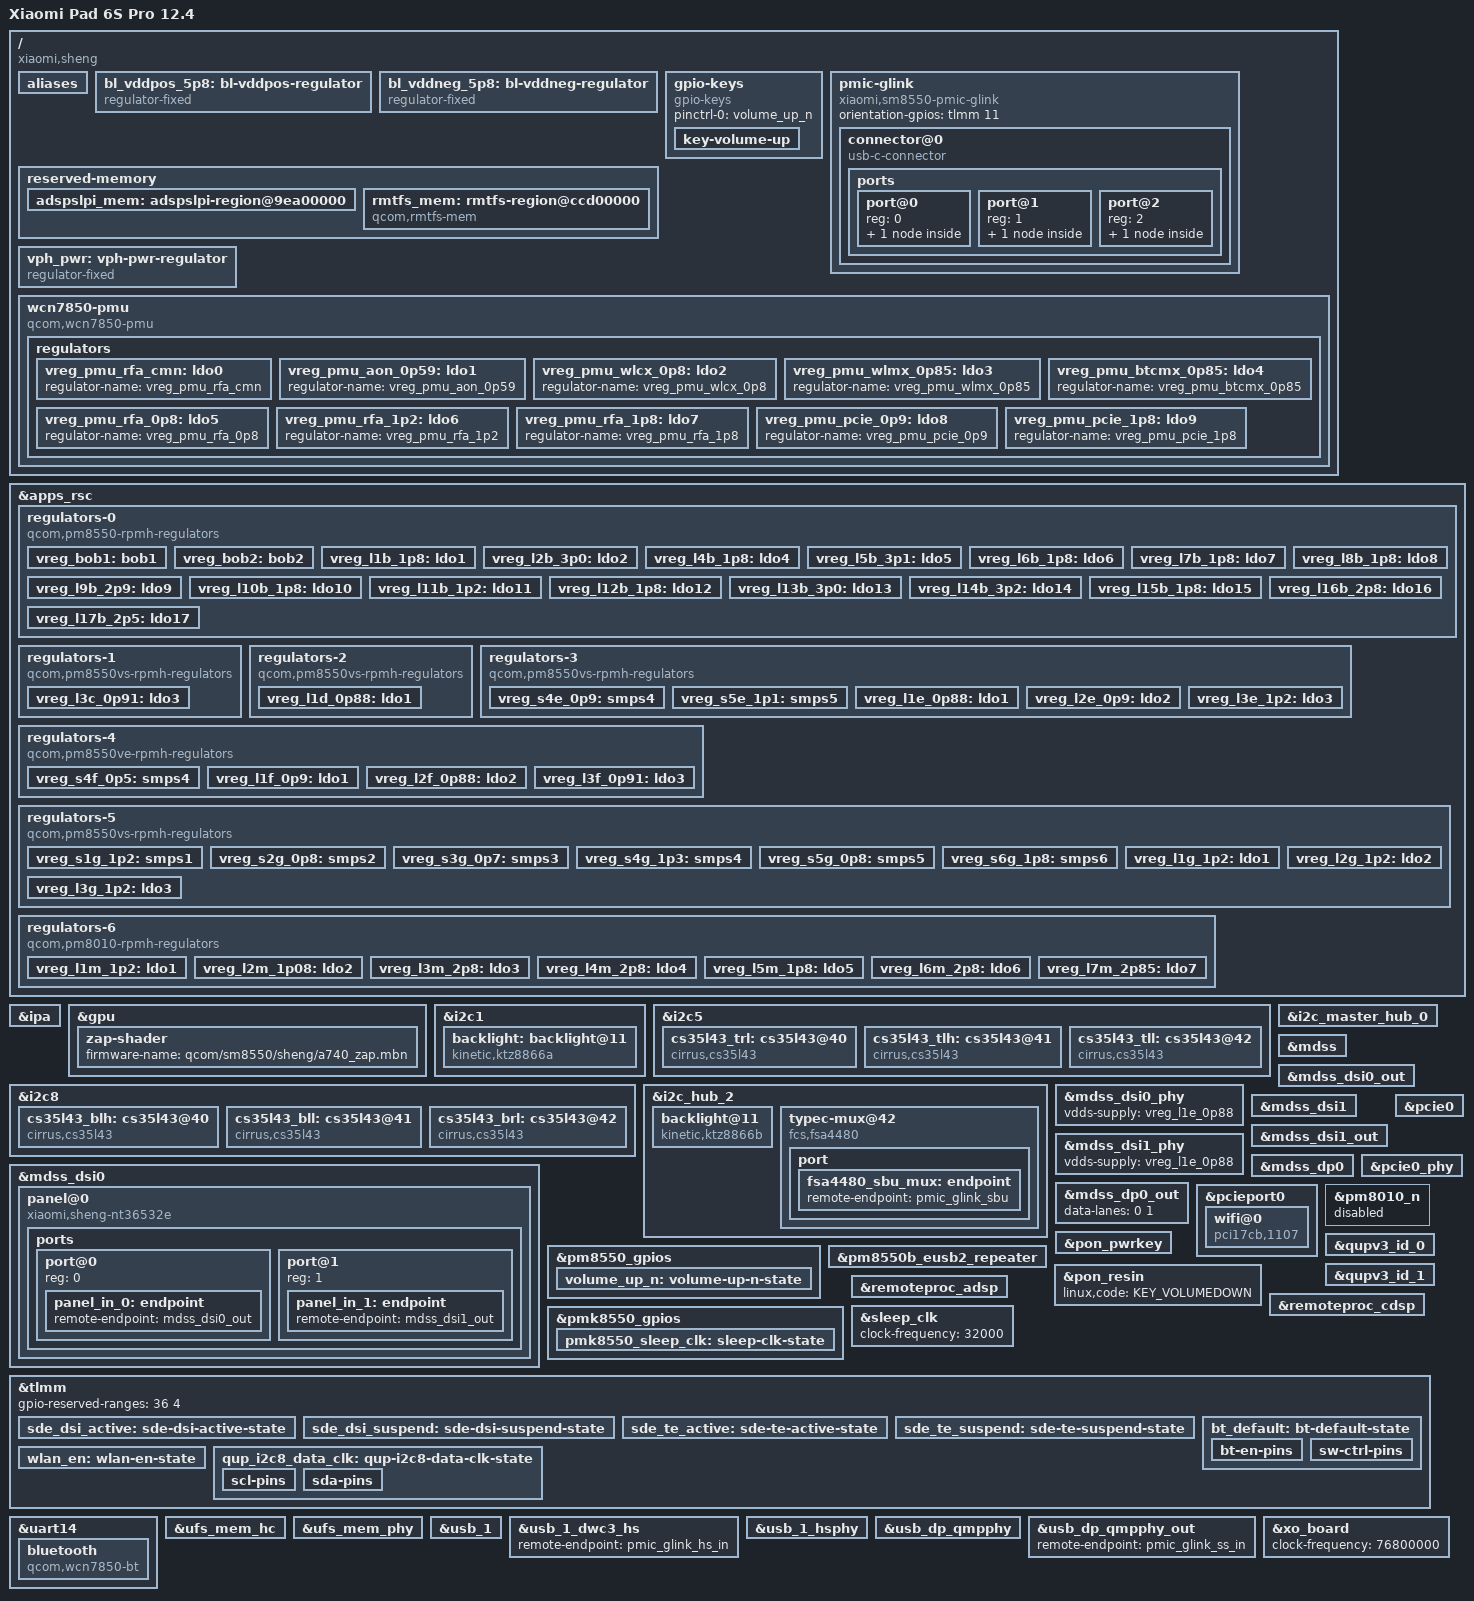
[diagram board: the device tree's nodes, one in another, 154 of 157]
// SPDX-License-Identifier: BSD-3-Clause
/*
 * Copyright (c) 2024, map220v <map220v300@gmail.com>
 */

/dts-v1/;

#include <dt-bindings/arm/qcom,ids.h>
#include <dt-bindings/regulator/qcom,rpmh-regulator.h>
#include "sm8550.dtsi"
#include "pm8010.dtsi"
#include "pm8550.dtsi"
#include "pm8550b.dtsi"
#define PMK8550VE_SID 5
#include "pm8550ve.dtsi"
#include "pm8550vs.dtsi"
#include "pmk8550.dtsi"

/delete-node/ &rmtfs_mem;
/delete-node/ &adspslpi_mem;

/* Xiaomi uses alternative gpio's for i2c8 */
/delete-node/ &qup_i2c8_data_clk;

/* SM8550P doesn't have Modem DSP */
/delete-node/ &mpss_dsm_mem;
/delete-node/ &mpss_mem;
/delete-node/ &q6_mpss_dtb_mem;
/delete-node/ &remoteproc_mpss;

/ {
	model = "Xiaomi Pad 6S Pro 12.4";
	compatible = "xiaomi,sheng", "qcom,sm8550";
	chassis-type = "tablet";
	qcom,msm-id = <536 0x20000>; /* SM8550P v2.0 */
	qcom,board-id = <0x10008 0>;

	aliases {
		serial0 = &uart7;
		serial1 = &uart14;
	};

	bl_vddpos_5p8: bl-vddpos-regulator {
		compatible = "regulator-fixed";
		regulator-name = "bl_vddpos_5p8";
		regulator-min-microvolt = <5800000>;
		regulator-max-microvolt = <5800000>;
		regulator-enable-ramp-delay = <233>;
		gpio = <&tlmm 30 GPIO_ACTIVE_HIGH>;
		enable-active-high;
	};

	bl_vddneg_5p8: bl-vddneg-regulator {
		compatible = "regulator-fixed";
		regulator-name = "bl_vddneg_5p8";
		regulator-min-microvolt = <5800000>;
		regulator-max-microvolt = <5800000>;
		regulator-enable-ramp-delay = <233>;
		gpio = <&tlmm 31 GPIO_ACTIVE_HIGH>;
		enable-active-high;
	};

	gpio-keys {
		compatible = "gpio-keys";

		pinctrl-0 = <&volume_up_n>;
		pinctrl-names = "default";

		key-volume-up {
			label = "Volume Up";
			linux,code = <KEY_VOLUMEUP>;
			gpios = <&pm8550_gpios 6 GPIO_ACTIVE_LOW>;
			debounce-interval = <15>;
			linux,can-disable;
			wakeup-source;
		};
	};

	pmic-glink {
		compatible = "xiaomi,sm8550-pmic-glink", "qcom,sm8550-pmic-glink", "qcom,pmic-glink";
		#address-cells = <1>;
		#size-cells = <0>;
		orientation-gpios = <&tlmm 11 GPIO_ACTIVE_HIGH>;

		connector@0 {
			compatible = "usb-c-connector";
			reg = <0>;
			power-role = "dual";
			data-role = "dual";

			ports {
				#address-cells = <1>;
				#size-cells = <0>;

				port@0 {
					reg = <0>;

					pmic_glink_hs_in: endpoint {
						remote-endpoint = <&usb_1_dwc3_hs>;
					};
				};

				port@1 {
					reg = <1>;

					pmic_glink_ss_in: endpoint {
						remote-endpoint = <&usb_dp_qmpphy_out>;
					};
				};

				port@2 {
					reg = <2>;

					pmic_glink_sbu: endpoint {
						remote-endpoint = <&fsa4480_sbu_mux>;
					};
				};
			};
		};
	};

	reserved-memory {
		adspslpi_mem: adspslpi-region@9ea00000 {
			reg = <0 0x9ea00000 0 0x4680000>;
			no-map;
		};

		rmtfs_mem: rmtfs-region@ccd00000 {
			compatible = "qcom,rmtfs-mem";
			reg = <0x0 0xccd00000 0x0 0x280000>;
			no-map;

			qcom,client-id = <1>;
			qcom,vmid = <QCOM_SCM_VMID_MSS_MSA>;
		};
	};

	vph_pwr: vph-pwr-regulator {
		compatible = "regulator-fixed";
		regulator-name = "vph_pwr";
		regulator-min-microvolt = <3700000>;
		regulator-max-microvolt = <3700000>;

		regulator-always-on;
		regulator-boot-on;
	};

	wcn7850-pmu {
		compatible = "qcom,wcn7850-pmu";

		pinctrl-names = "default";
		pinctrl-0 = <&wlan_en>, <&pmk8550_sleep_clk>;

		wlan-enable-gpios = <&tlmm 80 GPIO_ACTIVE_HIGH>;
		/*
		 * TODO Add bt-enable-gpios once the Bluetooth driver is
		 * converted to using the power sequencer.
		 */

		vdd-supply = <&vreg_s5g_0p8>;
		vddio-supply = <&vreg_l15b_1p8>;
		vddaon-supply = <&vreg_s2g_0p8>;
		vdddig-supply = <&vreg_s4e_0p9>;
		vddrfa1p2-supply = <&vreg_s4g_1p3>;
		vddrfa1p8-supply = <&vreg_s6g_1p8>;

		regulators {
			vreg_pmu_rfa_cmn: ldo0 {
				regulator-name = "vreg_pmu_rfa_cmn";
			};

			vreg_pmu_aon_0p59: ldo1 {
				regulator-name = "vreg_pmu_aon_0p59";
			};

			vreg_pmu_wlcx_0p8: ldo2 {
				regulator-name = "vreg_pmu_wlcx_0p8";
			};

			vreg_pmu_wlmx_0p85: ldo3 {
				regulator-name = "vreg_pmu_wlmx_0p85";
			};

			vreg_pmu_btcmx_0p85: ldo4 {
				regulator-name = "vreg_pmu_btcmx_0p85";
			};

			vreg_pmu_rfa_0p8: ldo5 {
				regulator-name = "vreg_pmu_rfa_0p8";
			};

			vreg_pmu_rfa_1p2: ldo6 {
				regulator-name = "vreg_pmu_rfa_1p2";
			};

			vreg_pmu_rfa_1p8: ldo7 {
				regulator-name = "vreg_pmu_rfa_1p8";
			};

			vreg_pmu_pcie_0p9: ldo8 {
				regulator-name = "vreg_pmu_pcie_0p9";
			};

			vreg_pmu_pcie_1p8: ldo9 {
				regulator-name = "vreg_pmu_pcie_1p8";
			};
		};
	};
};

&apps_rsc {
	regulators-0 {
		compatible = "qcom,pm8550-rpmh-regulators";
		qcom,pmic-id = "b";

		vdd-bob1-supply = <&vph_pwr>;
		vdd-bob2-supply = <&vph_pwr>;
		vdd-l1-l4-l10-supply = <&vreg_s6g_1p8>;
		vdd-l2-l13-l14-supply = <&vreg_bob1>;
		vdd-l3-supply = <&vreg_s4g_1p3>;
		vdd-l5-l16-supply = <&vreg_bob1>;
		vdd-l6-l7-supply = <&vreg_bob1>;
		vdd-l8-l9-supply = <&vreg_bob1>;
		vdd-l11-supply = <&vreg_s4g_1p3>;
		vdd-l12-supply = <&vreg_s6g_1p8>;
		vdd-l15-supply = <&vreg_s6g_1p8>;
		vdd-l17-supply = <&vreg_bob2>;

		vreg_bob1: bob1 {
			regulator-name = "vreg_bob1";
			regulator-min-microvolt = <3296000>;
			regulator-max-microvolt = <3960000>;
			regulator-initial-mode = <RPMH_REGULATOR_MODE_HPM>;
		};

		/* Xiaomi change for Camera Modules */
		vreg_bob2: bob2 {
			regulator-name = "vreg_bob2";
			regulator-min-microvolt = <2704000>;
			regulator-max-microvolt = <3296000>;
			regulator-initial-mode = <RPMH_REGULATOR_MODE_HPM>;
		};

		vreg_l1b_1p8: ldo1 {
			regulator-name = "vreg_l1b_1p8";
			regulator-min-microvolt = <1800000>;
			regulator-max-microvolt = <1800000>;
			regulator-initial-mode = <RPMH_REGULATOR_MODE_HPM>;
		};

		vreg_l2b_3p0: ldo2 {
			regulator-name = "vreg_l2b_3p0";
			regulator-min-microvolt = <3008000>;
			regulator-max-microvolt = <3008000>;
			regulator-initial-mode = <RPMH_REGULATOR_MODE_HPM>;
		};

		vreg_l4b_1p8: ldo4 {
			regulator-name = "vreg_l4b_1p8";
			regulator-min-microvolt = <1800000>;
			regulator-max-microvolt = <1800000>;
			regulator-initial-mode = <RPMH_REGULATOR_MODE_HPM>;
		};

		vreg_l5b_3p1: ldo5 {
			regulator-name = "vreg_l5b_3p1";
			regulator-min-microvolt = <3104000>;
			regulator-max-microvolt = <3104000>;
			regulator-initial-mode = <RPMH_REGULATOR_MODE_HPM>;
		};

		/* Xiaomi change for Nanosic WN803x */
		vreg_l6b_1p8: ldo6 {
			regulator-name = "vreg_l6b_1p8";
			regulator-min-microvolt = <1800000>;
			regulator-max-microvolt = <1800000>;
			regulator-initial-mode = <RPMH_REGULATOR_MODE_HPM>;
		};

		/* Xiaomi change for Camera Modules */
		vreg_l7b_1p8: ldo7 {
			regulator-name = "vreg_l7b_1p8";
			regulator-min-microvolt = <1800000>;
			regulator-max-microvolt = <1800000>;
			regulator-initial-mode = <RPMH_REGULATOR_MODE_HPM>;
		};

		/* Xiaomi change for Semtech SX9371 */
		vreg_l8b_1p8: ldo8 {
			regulator-name = "vreg_l8b_1p8";
			regulator-min-microvolt = <1800000>;
			regulator-max-microvolt = <1800000>;
			regulator-initial-mode = <RPMH_REGULATOR_MODE_HPM>;
			regulator-always-on;
			regulator-boot-on;
		};

		/* TODO: Xiaomi uses min/max 3300000 for FPC1552 */
		vreg_l9b_2p9: ldo9 {
			regulator-name = "vreg_l9b_2p9";
			regulator-min-microvolt = <2960000>;
			regulator-max-microvolt = <3008000>;
			regulator-initial-mode = <RPMH_REGULATOR_MODE_HPM>;
		};

		vreg_l10b_1p8: ldo10 {
			regulator-name = "vreg_l10b_1p8";
			regulator-min-microvolt = <1800000>;
			regulator-max-microvolt = <1800000>;
			regulator-initial-mode = <RPMH_REGULATOR_MODE_HPM>;
		};

		vreg_l11b_1p2: ldo11 {
			regulator-name = "vreg_l11b_1p2";
			regulator-min-microvolt = <1200000>;
			regulator-max-microvolt = <1504000>;
			regulator-initial-mode = <RPMH_REGULATOR_MODE_HPM>;
		};

		vreg_l12b_1p8: ldo12 {
			regulator-name = "vreg_l12b_1p8";
			regulator-min-microvolt = <1800000>;
			regulator-max-microvolt = <1800000>;
			regulator-initial-mode = <RPMH_REGULATOR_MODE_HPM>;
		};

		/* TODO: Xiaomi uses min/max 3300000 for Nanosic WN803x */
		vreg_l13b_3p0: ldo13 {
			regulator-name = "vreg_l13b_3p0";
			regulator-min-microvolt = <3000000>;
			regulator-max-microvolt = <3000000>;
			regulator-initial-mode = <RPMH_REGULATOR_MODE_HPM>;
		};

		vreg_l14b_3p2: ldo14 {
			regulator-name = "vreg_l14b_3p2";
			regulator-min-microvolt = <3200000>;
			regulator-max-microvolt = <3200000>;
			regulator-initial-mode = <RPMH_REGULATOR_MODE_HPM>;
		};

		vreg_l15b_1p8: ldo15 {
			regulator-name = "vreg_l15b_1p8";
			regulator-min-microvolt = <1800000>;
			regulator-max-microvolt = <1800000>;
			regulator-initial-mode = <RPMH_REGULATOR_MODE_HPM>;
		};

		vreg_l16b_2p8: ldo16 {
			regulator-name = "vreg_l16b_2p8";
			regulator-min-microvolt = <2800000>;
			regulator-max-microvolt = <2800000>;
			regulator-initial-mode = <RPMH_REGULATOR_MODE_HPM>;
		};

		vreg_l17b_2p5: ldo17 {
			regulator-name = "vreg_l17b_2p5";
			regulator-min-microvolt = <2504000>;
			regulator-max-microvolt = <2504000>;
			regulator-initial-mode = <RPMH_REGULATOR_MODE_HPM>;
		};
	};

	regulators-1 {
		compatible = "qcom,pm8550vs-rpmh-regulators";
		qcom,pmic-id = "c";

		vdd-l3-supply = <&vreg_s4e_0p9>;

		vreg_l3c_0p91: ldo3 {
			regulator-name = "vreg_l3c_0p9";
			regulator-min-microvolt = <880000>;
			regulator-max-microvolt = <912000>;
			regulator-initial-mode = <RPMH_REGULATOR_MODE_HPM>;
		};
	};

	regulators-2 {
		compatible = "qcom,pm8550vs-rpmh-regulators";
		qcom,pmic-id = "d";

		vdd-l1-supply = <&vreg_s4e_0p9>;

		vreg_l1d_0p88: ldo1 {
			regulator-name = "vreg_l1d_0p88";
			regulator-min-microvolt = <880000>;
			regulator-max-microvolt = <920000>;
			regulator-initial-mode = <RPMH_REGULATOR_MODE_HPM>;
		};
	};

	regulators-3 {
		compatible = "qcom,pm8550vs-rpmh-regulators";
		qcom,pmic-id = "e";

		vdd-l1-supply = <&vreg_s4e_0p9>;
		vdd-l2-supply = <&vreg_s4e_0p9>;
		vdd-l3-supply = <&vreg_s4g_1p3>;
		vdd-s4-supply = <&vph_pwr>;
		vdd-s5-supply = <&vph_pwr>;

		vreg_s4e_0p9: smps4 {
			regulator-name = "vreg_s4e_0p9";
			regulator-min-microvolt = <904000>;
			regulator-max-microvolt = <984000>;
			regulator-initial-mode = <RPMH_REGULATOR_MODE_HPM>;
		};

		vreg_s5e_1p1: smps5 {
			regulator-name = "vreg_s5e_1p1";
			regulator-min-microvolt = <1080000>;
			regulator-max-microvolt = <1120000>;
			regulator-initial-mode = <RPMH_REGULATOR_MODE_HPM>;
		};

		vreg_l1e_0p88: ldo1 {
			regulator-name = "vreg_l1e_0p88";
			regulator-min-microvolt = <880000>;
			regulator-max-microvolt = <880000>;
			regulator-initial-mode = <RPMH_REGULATOR_MODE_HPM>;
		};

		vreg_l2e_0p9: ldo2 {
			regulator-name = "vreg_l2e_0p9";
			regulator-min-microvolt = <904000>;
			regulator-max-microvolt = <970000>;
			regulator-initial-mode = <RPMH_REGULATOR_MODE_HPM>;
		};

		vreg_l3e_1p2: ldo3 {
			regulator-name = "vreg_l3e_1p2";
			regulator-min-microvolt = <1200000>;
			regulator-max-microvolt = <1200000>;
			regulator-initial-mode = <RPMH_REGULATOR_MODE_HPM>;
		};
	};

	regulators-4 {
		compatible = "qcom,pm8550ve-rpmh-regulators";
		qcom,pmic-id = "f";

		vdd-l1-supply = <&vreg_s4e_0p9>;
		vdd-l2-supply = <&vreg_s4e_0p9>;
		vdd-l3-supply = <&vreg_s4e_0p9>;
		vdd-s4-supply = <&vph_pwr>;

		vreg_s4f_0p5: smps4 {
			regulator-name = "vreg_s4f_0p5";
			regulator-min-microvolt = <500000>;
			regulator-max-microvolt = <700000>;
			regulator-initial-mode = <RPMH_REGULATOR_MODE_HPM>;
		};

		vreg_l1f_0p9: ldo1 {
			regulator-name = "vreg_l1f_0p9";
			regulator-min-microvolt = <912000>;
			regulator-max-microvolt = <912000>;
			regulator-initial-mode = <RPMH_REGULATOR_MODE_HPM>;
		};

		vreg_l2f_0p88: ldo2 {
			regulator-name = "vreg_l2f_0p88";
			regulator-min-microvolt = <880000>;
			regulator-max-microvolt = <912000>;
			regulator-initial-mode = <RPMH_REGULATOR_MODE_HPM>;
		};

		vreg_l3f_0p91: ldo3 {
			regulator-name = "vreg_l3f_0p91";
			regulator-min-microvolt = <880000>;
			regulator-max-microvolt = <912000>;
			regulator-initial-mode = <RPMH_REGULATOR_MODE_HPM>;
		};
	};

	regulators-5 {
		compatible = "qcom,pm8550vs-rpmh-regulators";
		qcom,pmic-id = "g";

		vdd-l1-supply = <&vreg_s4g_1p3>;
		vdd-l2-supply = <&vreg_s4g_1p3>;
		vdd-l3-supply = <&vreg_s4g_1p3>;
		vdd-s1-supply = <&vph_pwr>;
		vdd-s2-supply = <&vph_pwr>;
		vdd-s3-supply = <&vph_pwr>;
		vdd-s4-supply = <&vph_pwr>;
		vdd-s5-supply = <&vph_pwr>;
		vdd-s6-supply = <&vph_pwr>;

		vreg_s1g_1p2: smps1 {
			regulator-name = "vreg_s1g_1p2";
			regulator-min-microvolt = <1200000>;
			regulator-max-microvolt = <1300000>;
			regulator-initial-mode = <RPMH_REGULATOR_MODE_HPM>;
		};

		vreg_s2g_0p8: smps2 {
			regulator-name = "vreg_s2g_0p8";
			regulator-min-microvolt = <800000>;
			regulator-max-microvolt = <1000000>;
			regulator-initial-mode = <RPMH_REGULATOR_MODE_HPM>;
		};

		/* Xiaomi change for Display Panel */
		vreg_s3g_0p7: smps3 {
			regulator-name = "vreg_s3g_0p7";
			/* Min should be 1900000 */
			regulator-min-microvolt = <600000>;
			regulator-max-microvolt = <1900000>; //2004000
			regulator-initial-mode = <RPMH_REGULATOR_MODE_HPM>;
		};

		/* Xiaomi change for Camera Modules */
		vreg_s4g_1p3: smps4 {
			regulator-name = "vreg_s4g_1p3";
			regulator-min-microvolt = <1256000>;
			regulator-max-microvolt = <1408000>;
			regulator-initial-mode = <RPMH_REGULATOR_MODE_HPM>;
		};

		vreg_s5g_0p8: smps5 {
			regulator-name = "vreg_s5g_0p8";
			regulator-min-microvolt = <500000>;
			regulator-max-microvolt = <1004000>;
			regulator-initial-mode = <RPMH_REGULATOR_MODE_HPM>;
		};

		vreg_s6g_1p8: smps6 {
			regulator-name = "vreg_s6g_1p8";
			regulator-min-microvolt = <1800000>;
			regulator-max-microvolt = <2000000>;
			regulator-initial-mode = <RPMH_REGULATOR_MODE_HPM>;
		};

		vreg_l1g_1p2: ldo1 {
			regulator-name = "vreg_l1g_1p2";
			regulator-min-microvolt = <1200000>;
			regulator-max-microvolt = <1200000>;
			regulator-initial-mode = <RPMH_REGULATOR_MODE_HPM>;
		};

		vreg_l2g_1p2: ldo2 {
			regulator-name = "vreg_l2g_1p2";
			regulator-min-microvolt = <1200000>;
			regulator-max-microvolt = <1200000>;
			regulator-initial-mode = <RPMH_REGULATOR_MODE_HPM>;
		};

		vreg_l3g_1p2: ldo3 {
			regulator-name = "vreg_l3g_1p2";
			regulator-min-microvolt = <1200000>;
			regulator-max-microvolt = <1200000>;
			regulator-initial-mode = <RPMH_REGULATOR_MODE_HPM>;
		};
	};

	regulators-6 {
		compatible = "qcom,pm8010-rpmh-regulators";
		qcom,pmic-id = "m";

		vdd-l1-l2-supply = <&vreg_s4g_1p3>;
		vdd-l3-l4-supply = <&vreg_bob2>;
		vdd-l5-supply = <&vreg_s6g_1p8>;
		vdd-l6-supply = <&vreg_s6g_1p8>;
		vdd-l7-supply = <&vreg_bob1>;

		/* Xiaomi change for Camera Modules */
		vreg_l1m_1p2: ldo1 {
			regulator-name = "vreg_l1m_1p2";
			regulator-min-microvolt = <1200000>;
			regulator-max-microvolt = <1200000>;
			regulator-initial-mode = <RPMH_REGULATOR_MODE_HPM>;
		};

		/* Xiaomi change for Camera Modules */
		vreg_l2m_1p08: ldo2 {
			regulator-name = "vreg_l2m_1p08";
			regulator-min-microvolt = <1080000>;
			regulator-max-microvolt = <1080000>;
			regulator-initial-mode = <RPMH_REGULATOR_MODE_HPM>;
		};

		vreg_l3m_2p8: ldo3 {
			regulator-name = "vreg_l3m_2p8";
			regulator-min-microvolt = <2800000>;
			regulator-max-microvolt = <2800000>;
			regulator-initial-mode = <RPMH_REGULATOR_MODE_HPM>;
		};

		vreg_l4m_2p8: ldo4 {
			regulator-name = "vreg_l4m_2p8";
			regulator-min-microvolt = <2800000>;
			regulator-max-microvolt = <2800000>;
			regulator-initial-mode = <RPMH_REGULATOR_MODE_HPM>;
		};

		vreg_l5m_1p8: ldo5 {
			regulator-name = "vreg_l5m_1p8";
			regulator-min-microvolt = <1800000>;
			regulator-max-microvolt = <1800000>;
			regulator-initial-mode = <RPMH_REGULATOR_MODE_HPM>;
		};

		/* Xiaomi change for Camera Modules */
		vreg_l6m_2p8: ldo6 {
			regulator-name = "vreg_l6m_2p8";
			regulator-min-microvolt = <2800000>;
			regulator-max-microvolt = <2800000>;
			regulator-initial-mode = <RPMH_REGULATOR_MODE_HPM>;
		};

		/* Xiaomi change for Camera Modules */
		vreg_l7m_2p85: ldo7 {
			regulator-name = "vreg_l7m_2p85";
			regulator-min-microvolt = <2856000>;
			regulator-max-microvolt = <2856000>;
			regulator-initial-mode = <RPMH_REGULATOR_MODE_HPM>;
		};
	};
};

&ipa {
	qcom,gsi-loader = "self";
	memory-region = <&ipa_fw_mem>;
	firmware-name = "qcom/sm8550/sheng/ipa_fws.mbn";
	status = "okay";
};

&gpu {
	status = "okay";

	zap-shader {
		firmware-name = "qcom/sm8550/sheng/a740_zap.mbn";
	};
};

&i2c1 {
	status = "okay";

	backlight: backlight@11 {
		compatible = "kinetic,ktz8866a";
		reg = <0x11>;
		vddpos-supply = <&bl_vddpos_5p8>;
		vddneg-supply = <&bl_vddneg_5p8>;
		enable-gpios = <&tlmm 128 GPIO_ACTIVE_HIGH>;
		current-num-sinks = <5>;
		kinetic,current-ramp-delay-ms = <256>;
		kinetic,led-enable-ramp-delay-ms = <8>;
		kinetic,enable-lcd-bias;
	};
};

&i2c5 {
	status = "okay";

	cs35l43_trl: cs35l43@40 {
		compatible = "cirrus,cs35l43";
		reg = <0x40>;
		interrupt-parent = <&tlmm>;
		interrupts = <98 IRQ_TYPE_LEVEL_LOW>;
		reset-gpios = <&tlmm 90 GPIO_ACTIVE_HIGH>;
		#sound-dai-cells = <0>;
		sound-name-prefix = "TRL";
		cirrus,vpbr-thld = <8>;
		cirrus,vpbr-max-att = <3>;
		cirrus,vpbr-atk-vol = <5>;
		cirrus,vpbr-atk-rate = <0>;
		cirrus,vpbr-wait = <0>;
		cirrus,vpbr-rel-rate = <0>;
		cirrus,vpbr-enable = <1>;
		cirrus,gpio2-src-sel = <4>;
		cirrus,asp-sdout-hiz = <3>;
		cirrus,bst-ipk-ma = <4000>;
	};

	cs35l43_tlh: cs35l43@41 {
		compatible = "cirrus,cs35l43";
		reg = <0x41>;
		interrupt-parent = <&tlmm>;
		interrupts = <99 IRQ_TYPE_LEVEL_LOW>;
		reset-gpios = <&tlmm 90 GPIO_ACTIVE_HIGH>;
		#sound-dai-cells = <0>;
		sound-name-prefix = "TLH";
		cirrus,vpbr-thld = <8>;
		cirrus,vpbr-max-att = <3>;
		cirrus,vpbr-atk-vol = <5>;
		cirrus,vpbr-atk-rate = <0>;
		cirrus,vpbr-wait = <0>;
		cirrus,vpbr-rel-rate = <0>;
		cirrus,vpbr-enable = <1>;
		cirrus,gpio2-src-sel = <4>;
		cirrus,asp-sdout-hiz = <3>;
		cirrus,bst-ipk-ma = <4000>;
	};

	cs35l43_tll: cs35l43@42 {
		compatible = "cirrus,cs35l43";
		reg = <0x42>;
		interrupt-parent = <&tlmm>;
		interrupts = <119 IRQ_TYPE_LEVEL_LOW>;
		reset-gpios = <&tlmm 90 GPIO_ACTIVE_HIGH>;
		#sound-dai-cells = <0>;
		sound-name-prefix = "TLL";
		cirrus,vpbr-thld = <8>;
		cirrus,vpbr-max-att = <3>;
		cirrus,vpbr-atk-vol = <5>;
		cirrus,vpbr-atk-rate = <0>;
		cirrus,vpbr-wait = <0>;
		cirrus,vpbr-rel-rate = <0>;
		cirrus,vpbr-enable = <1>;
		cirrus,gpio2-src-sel = <4>;
		cirrus,asp-sdout-hiz = <3>;
		cirrus,bst-ipk-ma = <4000>;
	};
};

&i2c8 {
	status = "okay";

	cs35l43_blh: cs35l43@40 {
		compatible = "cirrus,cs35l43";
		reg = <0x40>;
		interrupt-parent = <&tlmm>;
		interrupts = <8 IRQ_TYPE_LEVEL_LOW>;
		reset-gpios = <&tlmm 90 GPIO_ACTIVE_HIGH>;
		#sound-dai-cells = <0>;
		sound-name-prefix = "BLH";
		cirrus,vpbr-thld = <8>;
		cirrus,vpbr-max-att = <3>;
		cirrus,vpbr-atk-vol = <5>;
		cirrus,vpbr-atk-rate = <0>;
		cirrus,vpbr-wait = <0>;
		cirrus,vpbr-rel-rate = <0>;
		cirrus,vpbr-enable = <1>;
		cirrus,gpio2-src-sel = <4>;
		cirrus,asp-sdout-hiz = <3>;
		cirrus,bst-ipk-ma = <4000>;
	};

	cs35l43_bll: cs35l43@41 {
		compatible = "cirrus,cs35l43";
		reg = <0x41>;
		interrupt-parent = <&tlmm>;
		interrupts = <17 IRQ_TYPE_LEVEL_LOW>;
		reset-gpios = <&tlmm 90 GPIO_ACTIVE_HIGH>;
		#sound-dai-cells = <0>;
		sound-name-prefix = "BLL";
		cirrus,vpbr-thld = <8>;
		cirrus,vpbr-max-att = <3>;
		cirrus,vpbr-atk-vol = <5>;
		cirrus,vpbr-atk-rate = <0>;
		cirrus,vpbr-wait = <0>;
		cirrus,vpbr-rel-rate = <0>;
		cirrus,vpbr-enable = <1>;
		cirrus,gpio2-src-sel = <4>;
		cirrus,asp-sdout-hiz = <3>;
		cirrus,bst-ipk-ma = <4000>;
	};

	cs35l43_brl: cs35l43@42 {
		compatible = "cirrus,cs35l43";
		reg = <0x42>;
		interrupt-parent = <&tlmm>;
		interrupts = <85 IRQ_TYPE_LEVEL_LOW>;
		reset-gpios = <&tlmm 90 GPIO_ACTIVE_HIGH>;
		#sound-dai-cells = <0>;
		sound-name-prefix = "BRL";
		cirrus,vpbr-thld = <8>;
		cirrus,vpbr-max-att = <3>;
		cirrus,vpbr-atk-vol = <5>;
		cirrus,vpbr-atk-rate = <0>;
		cirrus,vpbr-wait = <0>;
		cirrus,vpbr-rel-rate = <0>;
		cirrus,vpbr-enable = <1>;
		cirrus,gpio2-src-sel = <4>;
		cirrus,asp-sdout-hiz = <3>;
		cirrus,bst-ipk-ma = <4000>;
	};
};

&i2c_master_hub_0 {
	status = "okay";
};

&i2c_hub_2 {
	status = "okay";

	backlight@11 {
		compatible = "kinetic,ktz8866b";
		reg = <0x11>;
		vddpos-supply = <&bl_vddpos_5p8>;
		vddneg-supply = <&bl_vddneg_5p8>;
		enable-gpios = <&tlmm 128 GPIO_ACTIVE_HIGH>;
		current-num-sinks = <5>;
		kinetic,current-ramp-delay-ms = <256>;
		kinetic,led-enable-ramp-delay-ms = <8>;
		kinetic,enable-lcd-bias;
	};

	typec-mux@42 {
		compatible = "fcs,fsa4480";
		reg = <0x42>;

		vcc-supply = <&vreg_bob1>;

		mode-switch;
		orientation-switch;

		port {
			fsa4480_sbu_mux: endpoint {
				remote-endpoint = <&pmic_glink_sbu>;
			};
		};
	};
};

&mdss {
	status = "okay";
};

&mdss_dsi0 {
	vdda-supply = <&vreg_l3e_1p2>;
	qcom,dual-dsi-mode;
	qcom,sync-dual-dsi;
	qcom,master-dsi;
	status = "okay";

	panel@0 {
		compatible = "xiaomi,sheng-nt36532e", "novatek,nt36532e";
		reg = <0>;

		pinctrl-names = "default", "sleep";
		pinctrl-0 = <&sde_dsi_active>, <&sde_te_active>;
		pinctrl-1 = <&sde_dsi_suspend>, <&sde_te_suspend>;

		vddio-supply = <&vreg_s3g_0p7>;
		reset-gpios = <&tlmm 133 GPIO_ACTIVE_LOW>;
		backlight = <&backlight>;

		ports {
			#address-cells = <1>;
			#size-cells = <0>;

			port@0 {
				reg = <0>;

				panel_in_0: endpoint {
					remote-endpoint = <&mdss_dsi0_out>;
				};
			};

			port@1 {
				reg = <1>;
	
				panel_in_1: endpoint {
					remote-endpoint = <&mdss_dsi1_out>;
				};
			};
		};
	};
};

&mdss_dsi0_out {
	remote-endpoint = <&panel_in_0>;
	data-lanes = <0 1 2 3>;
};

&mdss_dsi0_phy {
	vdds-supply = <&vreg_l1e_0p88>;
	status = "okay";
};

&mdss_dsi1 {
	vdda-supply = <&vreg_l3e_1p2>;
	qcom,dual-dsi-mode;
	qcom,sync-dual-dsi;
	/* DSI1 is slave, so use DSI0 clocks */
	assigned-clock-parents = <&mdss_dsi0_phy 0>, <&mdss_dsi0_phy 1>;
	status = "okay";
};

&mdss_dsi1_out {
	remote-endpoint = <&panel_in_1>;
	data-lanes = <0 1 2 3>;
};

&mdss_dsi1_phy {
	vdds-supply = <&vreg_l1e_0p88>;
	status = "okay";
};

&mdss_dp0 {
	status = "okay";
};

&mdss_dp0_out {
	data-lanes = <0 1>;
};

&pcie0 {
	wake-gpios = <&tlmm 96 GPIO_ACTIVE_HIGH>;
	perst-gpios = <&tlmm 94 GPIO_ACTIVE_LOW>;

	pinctrl-names = "default";
	pinctrl-0 = <&pcie0_default_state>;

	status = "okay";
};

&pcieport0 {
	wifi@0 {
		compatible = "pci17cb,1107";
		reg = <0x10000 0x0 0x0 0x0 0x0>;

		vddrfacmn-supply = <&vreg_pmu_rfa_cmn>;
		vddaon-supply = <&vreg_pmu_aon_0p59>;
		vddwlcx-supply = <&vreg_pmu_wlcx_0p8>;
		vddwlmx-supply = <&vreg_pmu_wlmx_0p85>;
		vddrfa0p8-supply = <&vreg_pmu_rfa_0p8>;
		vddrfa1p2-supply = <&vreg_pmu_rfa_1p2>;
		vddrfa1p8-supply = <&vreg_pmu_rfa_1p8>;
		vddpcie0p9-supply = <&vreg_pmu_pcie_0p9>;
		vddpcie1p8-supply = <&vreg_pmu_pcie_1p8>;
	};
};

&pcie0_phy {
	vdda-phy-supply = <&vreg_l1e_0p88>;
	vdda-pll-supply = <&vreg_l3e_1p2>;

	status = "okay";
};

&pm8010_n {
	status = "disabled";
};

&pm8550_gpios {
	volume_up_n: volume-up-n-state {
		pins = "gpio6";
		function = "normal";
		power-source = <1>;
		bias-pull-up;
		input-enable;
	};
};

&pm8550b_eusb2_repeater {
	vdd18-supply = <&vreg_l15b_1p8>;
	vdd3-supply = <&vreg_l5b_3p1>;
};

&pon_pwrkey {
	status = "okay";
};

&pon_resin {
	linux,code = <KEY_VOLUMEDOWN>;

	status = "okay";
};

&pmk8550_gpios {
	pmk8550_sleep_clk: sleep-clk-state {
		pins = "gpio3";
		function = "func1";
		input-disable;
		output-enable;
		bias-disable;
		power-source = <0>;
	};
};

&qupv3_id_0 {
	status = "okay";
};

&qupv3_id_1 {
	status = "okay";
};

&remoteproc_adsp {
	firmware-name = "qcom/sm8550/sheng/adsp.mbn",
			"qcom/sm8550/sheng/adsp_dtb.mbn";
	status = "okay";
};

&remoteproc_cdsp {
	firmware-name = "qcom/sm8550/sheng/cdsp.mbn",
			"qcom/sm8550/sheng/cdsp_dtb.mbn";
	status = "okay";
};

&sleep_clk {
	clock-frequency = <32000>;
};

&tlmm {
	gpio-reserved-ranges = <36 4>;

	sde_dsi_active: sde-dsi-active-state {
		pins = "gpio133";
		function = "gpio";
		drive-strength = <8>;
		bias-disable;
	};

	sde_dsi_suspend: sde-dsi-suspend-state {
		pins = "gpio133";
		function = "gpio";
		drive-strength = <2>;
		bias-pull-down;
	};

	sde_te_active: sde-te-active-state {
		pins = "gpio86";
		function = "mdp_vsync";
		drive-strength = <2>;
		bias-pull-down;
	};

	sde_te_suspend: sde-te-suspend-state {
		pins = "gpio86";
		function = "mdp_vsync";
		drive-strength = <2>;
		bias-pull-down;
	};

	bt_default: bt-default-state {
		bt-en-pins {
			pins = "gpio81";
			function = "gpio";
			drive-strength = <16>;
			bias-disable;
		};

		sw-ctrl-pins {
			pins = "gpio82";
			function = "gpio";
			bias-pull-down;
		};
	};

	wlan_en: wlan-en-state {
		pins = "gpio80";
		function = "gpio";
		drive-strength = <8>;
		bias-pull-down;
	};

	qup_i2c8_data_clk: qup-i2c8-data-clk-state {
		scl-pins {
			pins = "gpio1";
			function = "qup2_se0_l1_mirb";
			drive-strength = <2>;
			bias-pull-up = <2200>;
		};

		sda-pins {
			pins = "gpio0";
			function = "qup2_se0_l0_mirb";
			drive-strength = <2>;
			bias-pull-up = <2200>;
		};
	};
};

&uart14 {
	status = "okay";

	bluetooth {
		compatible = "qcom,wcn7850-bt";

		local-bd-address = [ 24 00 00 00 5a ad ];

		vddio-supply = <&vreg_l15b_1p8>;
		vddaon-supply = <&vreg_s4e_0p9>;
		vdddig-supply = <&vreg_s4e_0p9>;
		vddrfa0p8-supply = <&vreg_s4e_0p9>;
		vddrfa1p2-supply = <&vreg_s4g_1p3>;
		vddrfa1p9-supply = <&vreg_s6g_1p8>;

		max-speed = <3200000>;

		enable-gpios = <&tlmm 81 GPIO_ACTIVE_HIGH>;
		swctrl-gpios = <&tlmm 82 GPIO_ACTIVE_HIGH>;

		pinctrl-0 = <&bt_default>;
		pinctrl-names = "default";
	};
};

&ufs_mem_hc {
	reset-gpios = <&tlmm 210 GPIO_ACTIVE_LOW>;
	vcc-supply = <&vreg_l17b_2p5>;
	vcc-max-microamp = <1300000>;
	vccq-supply = <&vreg_l1g_1p2>;
	vccq-max-microamp = <1200000>;
	vdd-hba-supply = <&vreg_l3g_1p2>;

	status = "okay";
};

&ufs_mem_phy {
	vdda-phy-supply = <&vreg_l1d_0p88>;
	vdda-pll-supply = <&vreg_l3e_1p2>;

	status = "okay";
};

&usb_1 {
	status = "okay";
};

&usb_1_dwc3_hs {
	remote-endpoint = <&pmic_glink_hs_in>;
};

&usb_1_hsphy {
	vdd-supply = <&vreg_l1e_0p88>;
	vdda12-supply = <&vreg_l3e_1p2>;

	phys = <&pm8550b_eusb2_repeater>;

	status = "okay";
};

&usb_dp_qmpphy {
	vdda-phy-supply = <&vreg_l3e_1p2>;
	vdda-pll-supply = <&vreg_l3f_0p91>;

	status = "okay";
};

&usb_dp_qmpphy_out {
	remote-endpoint = <&pmic_glink_ss_in>;
};

&xo_board {
	clock-frequency = <76800000>;
};
